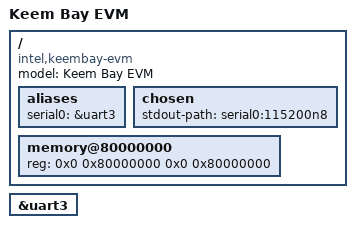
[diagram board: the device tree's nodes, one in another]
/dts-v1/;
#include "keembay-soc.dtsi"
/ {
	model = "Keem Bay EVM";
	compatible = "intel,keembay-evm", "intel,keembay";
	#address-cells = <2>;
	#size-cells = <2>;
	aliases {
		serial0 = &uart3;
	};
	chosen {
		stdout-path = "serial0:115200n8";
	};
	memory@80000000 {
		device_type = "memory";
		reg = <0x0 0x80000000 0x0 0x80000000>;
	};
};
&uart3 {
	status = "okay";
};
